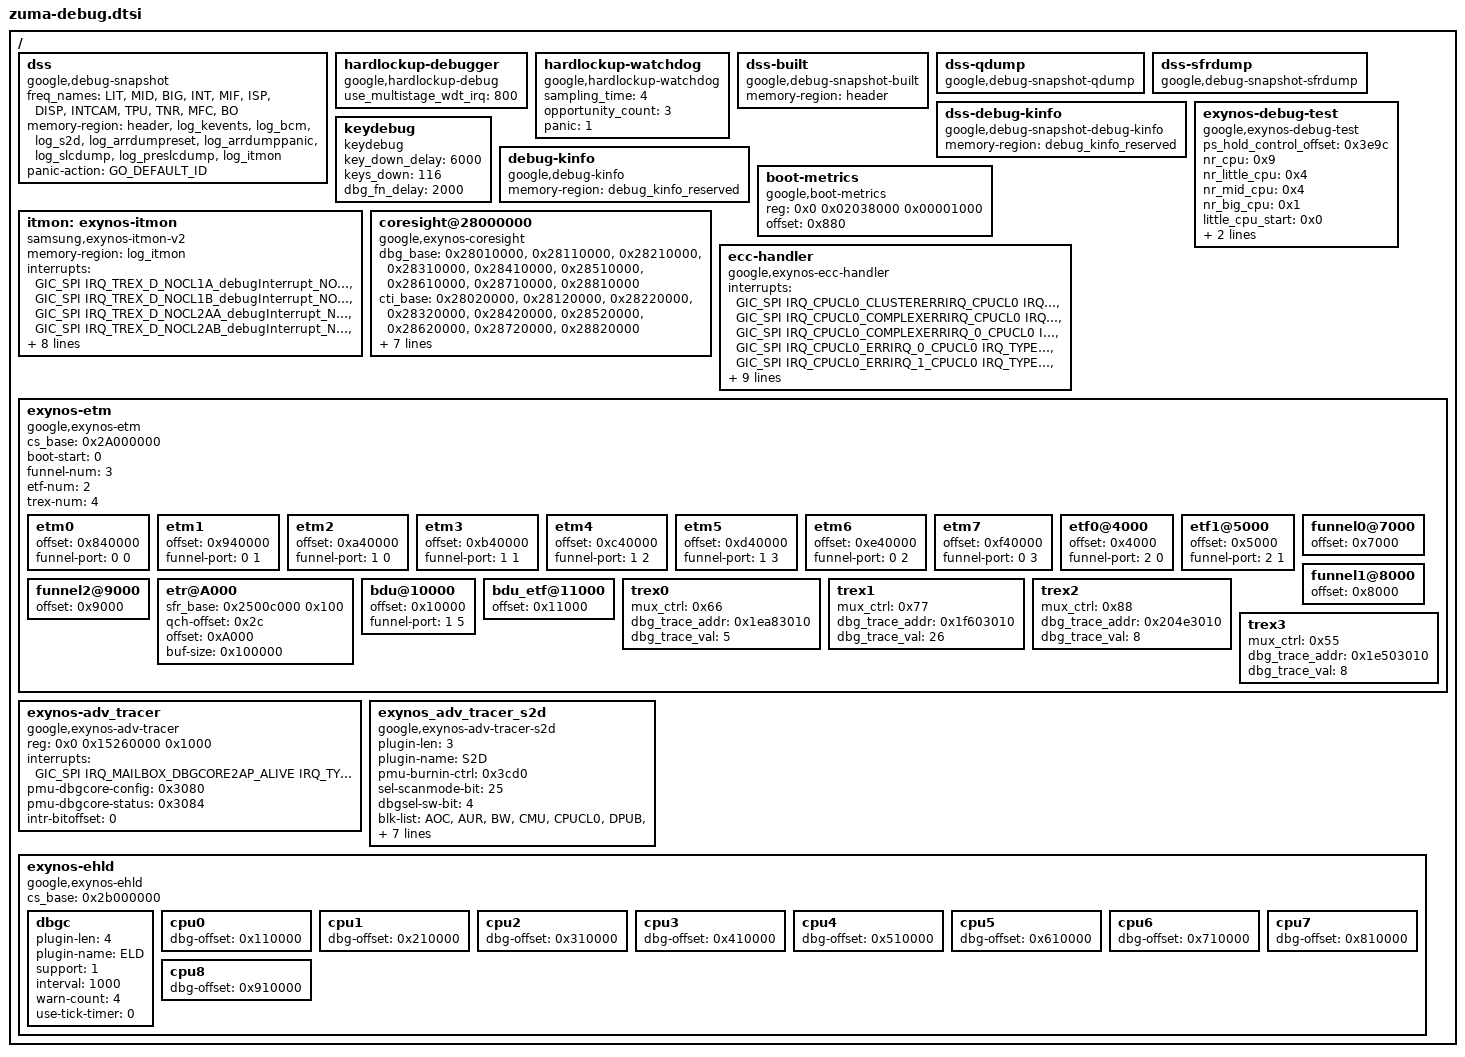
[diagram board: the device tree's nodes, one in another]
// SPDX-License-Identifier: GPL-2.0-only
/*
 * debug device tree source code for Zuma SoC
 *
 * Copyright 2022 Google LLC.
 */

#include <dt-bindings/interrupt-controller/zuma.h>
#include "zuma-dpm.dtsi"
#include "zuma-ppmu.dtsi"
/ {
	dss: dss {
		compatible = "google,debug-snapshot";
		freq_names = "LIT", "MID", "BIG", "INT", "MIF", "ISP",
				"DISP", "INTCAM", "TPU", "TNR", "MFC",
				"BO";
		memory-region = <&header>, <&log_kevents>, <&log_bcm>, <&log_s2d>,
				<&log_arrdumpreset>, <&log_arrdumppanic>,
				<&log_slcdump>, <&log_preslcdump>,
				<&log_itmon>;
		panic-action = <GO_DEFAULT_ID>;
	};

	hardlockup-debugger {
		compatible = "google,hardlockup-debug";
		use_multistage_wdt_irq = <800>;
	};

	hardlockup-watchdog {
		compatible = "google,hardlockup-watchdog";
		sampling_time = <4>;
		opportunity_count = <3>;
		panic = <1>;
	};

	dss-built {
		compatible = "google,debug-snapshot-built";
		memory-region = <&header>;
	};

	dss-qdump {
		compatible = "google,debug-snapshot-qdump";
	};

	dss-sfrdump {
		compatible = "google,debug-snapshot-sfrdump";
		/*
		 * -----------<< Example >>-------------------
		 * dump-info {
		 *	#address-cells = <1>;
		 *	#size-cells = <1>;
		 *
		 *	gic-setenable {
		 *		reg = <0x11f01100 0x100>;
		 *	};
		 *	gic-setpend {
		 *		reg = <0x11f01200 0x100>;
		 *	};
		 *	gic-setactive {
		 *		reg = <0x11f01300 0x100>;
		 *	};
		 *};
		 */
	};

	dss-debug-kinfo {
		compatible = "google,debug-snapshot-debug-kinfo";
		memory-region = <&debug_kinfo_reserved>;
	};

	exynos-debug-test {
		compatible = "google,exynos-debug-test";
		ps_hold_control_offset = <0x3e9c>;
		nr_cpu = <0x9>;
		nr_little_cpu = <0x4>;
		nr_mid_cpu = <0x4>;
		nr_big_cpu = <0x1>;
		little_cpu_start = <0x0>;
		mid_cpu_start = <0x4>;
		big_cpu_start = <0x8>;
	};

	keydebug {
		compatible = "keydebug";
		key_down_delay = <6000>;
		keys_down = <116>;
		dbg_fn_delay = <2000>;
	};

	debug-kinfo {
		compatible = "google,debug-kinfo";
		memory-region = <&debug_kinfo_reserved>;
	};

	boot-metrics {
		compatible = "google,boot-metrics";

		reg = <0x0 0x02038000 0x00001000>;
		reg-names = "ns_sram_base";
		offset = <0x880>;
	};

	itmon: exynos-itmon {
		compatible = "samsung,exynos-itmon-v2";
		memory-region = <&log_itmon>;
		interrupts =
			<GIC_SPI IRQ_TREX_D_NOCL1A_debugInterrupt_NOCL1A
							IRQ_TYPE_LEVEL_HIGH>,
			<GIC_SPI IRQ_TREX_D_NOCL1B_debugInterrupt_NOCL1B
							IRQ_TYPE_LEVEL_HIGH>,
			<GIC_SPI IRQ_TREX_D_NOCL2AA_debugInterrupt_NOCL2AA
							IRQ_TYPE_LEVEL_HIGH>,
			<GIC_SPI IRQ_TREX_D_NOCL2AB_debugInterrupt_NOCL2AB
							IRQ_TYPE_LEVEL_HIGH>,
			<GIC_SPI IRQ_TREX_D_NOCL0_debugInterrupt_NOCL0
							IRQ_TYPE_LEVEL_HIGH>,
			<GIC_SPI IRQ_TREX_P_NOCL1A_debugInterrupt_NOCL1A
							IRQ_TYPE_LEVEL_HIGH>,
			<GIC_SPI IRQ_TREX_P_NOCL1B_debugInterrupt_NOCL1B
							IRQ_TYPE_LEVEL_HIGH>,
			<GIC_SPI IRQ_TREX_P_NOCL2AA_debugInterrupt_NOCL2AA
							IRQ_TYPE_LEVEL_HIGH>,
			<GIC_SPI IRQ_TREX_P_NOCL2AB_debugInterrupt_NOCL2AB
							IRQ_TYPE_LEVEL_HIGH>,
			<GIC_SPI IRQ_TREX_P_NOCL0_debugInterrupt_NOCL0
							IRQ_TYPE_LEVEL_HIGH>;
		interrupt-affinity = <0xff>;
		support-irq-oring;
		status = "ok";
	};

	coresight@28000000 {
		compatible = "google,exynos-coresight";
		dbg_base = <0x28010000>, <0x28110000>, <0x28210000>, <0x28310000>,
			   <0x28410000>, <0x28510000>, <0x28610000>, <0x28710000>, <0x28810000>;
		cti_base = <0x28020000>, <0x28120000>, <0x28220000>, <0x28320000>,
			   <0x28420000>, <0x28520000>, <0x28620000>, <0x28720000>, <0x28820000>;
		pmu_base = <0x28030000>, <0x28130000>, <0x28230000>, <0x28330000>,
			   <0x28430000>, <0x28530000>, <0x28630000>, <0x28730000>, <0x28830000>;
		gpr_base = <0x2A001000>;
		dbgack-mask = <0xff00000>;
		halt = <1>;
		retention = <1>;
		status = "okay";
	};

	ecc-handler {
		compatible = "google,exynos-ecc-handler";
		interrupts = <GIC_SPI IRQ_CPUCL0_CLUSTERERRIRQ_CPUCL0 IRQ_TYPE_LEVEL_HIGH>,
			<GIC_SPI IRQ_CPUCL0_COMPLEXERRIRQ_CPUCL0 IRQ_TYPE_LEVEL_HIGH>,
			<GIC_SPI IRQ_CPUCL0_COMPLEXERRIRQ_0_CPUCL0 IRQ_TYPE_LEVEL_HIGH>,
			<GIC_SPI IRQ_CPUCL0_ERRIRQ_0_CPUCL0 IRQ_TYPE_LEVEL_HIGH>, /* CORE0 */
			<GIC_SPI IRQ_CPUCL0_ERRIRQ_1_CPUCL0 IRQ_TYPE_LEVEL_HIGH>, /* CORE1 */
			<GIC_SPI IRQ_CPUCL0_ERRIRQ_2_CPUCL0 IRQ_TYPE_LEVEL_HIGH>, /* CORE2 */
			<GIC_SPI IRQ_CPUCL0_ERRIRQ_3_CPUCL0 IRQ_TYPE_LEVEL_HIGH>, /* CORE3 */
			<GIC_SPI IRQ_CPUCL0_ERRIRQ_4_CPUCL0 IRQ_TYPE_LEVEL_HIGH>, /* CORE4 */
			<GIC_SPI IRQ_CPUCL0_ERRIRQ_5_CPUCL0 IRQ_TYPE_LEVEL_HIGH>, /* CORE5 */
			<GIC_SPI IRQ_CPUCL0_ERRIRQ_6_CPUCL0 IRQ_TYPE_LEVEL_HIGH>, /* CORE6 */
			<GIC_SPI IRQ_CPUCL0_ERRIRQ_7_CPUCL0 IRQ_TYPE_LEVEL_HIGH>, /* CORE7 */
			<GIC_SPI IRQ_CPUCL0_ERRIRQ_8_CPUCL0 IRQ_TYPE_LEVEL_HIGH>; /* CORE8 */
		interrupt-names = "Uncorrectable errors on the L3 data, tag or snoop filter RAMs",
			"Core0-1 Complex, Uncorrectable errors on the L2 data or tag RAMs",
			"Core2-3 Complex, Uncorrectable errors on the L2 data or tag RAMs",
			"Core0, Uncorrectable errors on the L1 data or tag RAMs",
			"Core1, Uncorrectable errors on the L1 data or tag RAMs",
			"Core2, Uncorrectable errors on the L1 data or tag RAMs",
			"Core3, Uncorrectable errors on the L1 data or tag RAMs",
			"Core4, Uncorrectable errors on the L1 data, tag or L2 data, tag RAMs",
			"Core5, Uncorrectable errors on the L1 data, tag or L2 data, tag RAMs",
			"Core6, Uncorrectable errors on the L1 data, tag or L2 data, tag RAMs",
			"Core7, Uncorrectable errors on the L1 data, tag or L2 data, tag RAMs",
			"Core8, Uncorrectable errors on the L1 data, tag or L2 data, tag RAMs";
		interrupt-affinity = <0x1ff>, <0x3>, <0xc>,
			<0x1>, <0x2>, <0x4>, <0x8>,
			<0x10>, <0x20>, <0x40>, <0x80>, <0x100>;
	};

	exynos-etm {
		compatible = "google,exynos-etm";
		cs_base = <0x2A000000>;
		boot-start = <0>;
		funnel-num = <3>;
		etf-num = <2>;
		trex-num = <4>;
		/* funnel-port = <(funnel num) (port num)>; */
		etm0 {
			device_type = "etm";
			offset = <0x840000>;
			funnel-port = <0 0>;
		};
		etm1 {
			device_type = "etm";
			offset = <0x940000>;
			funnel-port = <0 1>;
		};
		etm2 {
			device_type = "etm";
			offset = <0xa40000>;
			funnel-port = <1 0>;
		};
		etm3 {
			device_type = "etm";
			offset = <0xb40000>;
			funnel-port = <1 1>;
		};
		etm4 {
			device_type = "etm";
			offset = <0xc40000>;
			funnel-port = <1 2>;
		};
		etm5 {
			device_type = "etm";
			offset = <0xd40000>;
			funnel-port = <1 3>;
		};
		etm6 {
			device_type = "etm";
			offset = <0xe40000>;
			funnel-port = <0 2>;
		};
		etm7 {
			device_type = "etm";
			offset = <0xf40000>;
			funnel-port = <0 3>;
		};
		etf0@4000 {
			device_type = "etf";
			offset = <0x4000>;
			funnel-port = <2 0>;
		};
		etf1@5000 {
			device_type = "etf";
			offset = <0x5000>;
			funnel-port = <2 1>;
		};
		funnel0@7000 {
			device_type = "funnel";
			offset = <0x7000>;
		};
		funnel1@8000 {
			device_type = "funnel";
			offset = <0x8000>;
		};
		funnel2@9000 {
			device_type = "funnel";
			offset = <0x9000>;
		};
		etr@A000 {
			device_type = "etr";
			sfr_base = <0x2500c000 0x100>;
			qch-offset = <0x2c>;
			offset = <0xA000>;
			buf-size = <0x100000>;
		};
		bdu@10000 {
			device_type = "bdu";
			offset = <0x10000>;
			funnel-port = <1 5>;
		};
		bdu_etf@11000 {
			device_type = "bdu_etf";
			offset = <0x11000>;
		};
		trex0 {
			device_type = "trex";
			mux_ctrl = <0x66>;
			dbg_trace_addr = <0x1ea83010>;
			dbg_trace_val = <5>;
		};
		trex1 {
			device_type = "trex";
			mux_ctrl = <0x77>;
			dbg_trace_addr = <0x1f603010>;
			dbg_trace_val = <26>;
		};
		trex2 {
			device_type = "trex";
			mux_ctrl = <0x88>;
			dbg_trace_addr = <0x204e3010>;
			dbg_trace_val = <8>;
		};
		trex3 {
			device_type = "trex";
			mux_ctrl = <0x55>;
			dbg_trace_addr = <0x1e503010>;
			dbg_trace_val = <8>;
		};
	};

	exynos-adv_tracer {
		compatible = "google,exynos-adv-tracer";
		reg = <0x0 0x15260000 0x1000>;
		reg-names = "mailbox";
		interrupts = <GIC_SPI IRQ_MAILBOX_DBGCORE2AP_ALIVE IRQ_TYPE_LEVEL_HIGH>;
		pmu-dbgcore-config = <0x3080>;
		pmu-dbgcore-status = <0x3084>;
		intr-bitoffset = <0>;
		status = "okay";
	};

	exynos_adv_tracer_s2d {
		compatible = "google,exynos-adv-tracer-s2d";
		plugin-len = <3>;
		plugin-name = "S2D";
		pmu-burnin-ctrl = <0x3cd0>;
		sel-scanmode-bit = <25>;
		dbgsel-sw-bit = <4>;
		blk-list = "AOC", "AUR", "BW", "CMU", "CPUCL0", "DPUB",
			   "DPUF0", "DPUF1", "EH", "G2D", "G3D", "GDC",
			   "GSA", "GSE", "HSI0", "HSI1", "HSI2", "ISPFE",
			   "MCSC", "MFC", "MIF0", "MIF1", "MIF2", "MIF3",
			   "MISC", "NOCL0", "NOCL1A", "NOCL1B", "NOCL2AA", "NOCL2AB",
			   "PERIC0", "PERIC1", "RGBP", "TNR", "TPU", "YUVP",
			   "CLUSTER0", "GPU", "AOCCORE", "AURCORE", "BWCORE","TPUCORE",
			   "ISPFECORE", "SLC0", "SLC1", "SLC2", "SLC3";

		status = "okay";
	};

	exynos-ehld {
		compatible = "google,exynos-ehld";
		#address-cells = <1>;
		#size-cells = <1>;
		cs_base = <0x2b000000>;
		status = "ok";

		dbgc {
			/* IPC */
			plugin-len = <4>;
			plugin-name = "ELD";
			support = <1>;
			interval = <1000>;
			warn-count = <4>;
			use-tick-timer = <0>;
		};

		cpu0 {
			dbg-offset = <0x110000>;
		};
		cpu1 {
			dbg-offset = <0x210000>;
		};
		cpu2 {
			dbg-offset = <0x310000>;
		};
		cpu3 {
			dbg-offset = <0x410000>;
		};
		cpu4 {
			dbg-offset = <0x510000>;
		};
		cpu5 {
			dbg-offset = <0x610000>;
		};
		cpu6 {
			dbg-offset = <0x710000>;
		};
		cpu7 {
			dbg-offset = <0x810000>;
		};
		cpu8 {
			dbg-offset = <0x910000>;
		};
	};
};
